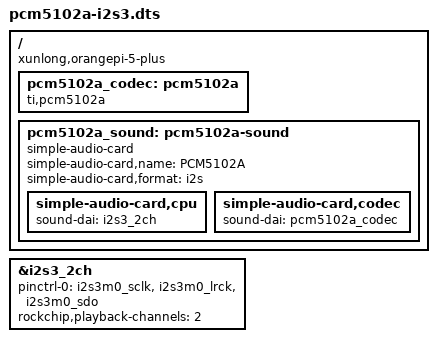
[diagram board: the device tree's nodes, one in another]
// Device Tree Overlay: PCM5102A I2S DAC on GPIO header (I2S3)
//
// Enables the RK3588/RK3588S I2S3 controller and registers a PCM5102A DAC
// connected to the 40-pin GPIO header as an ALSA sound card.
//
// Wiring:
//   Pin 35 (GPIO3_C2) → BCK  (bit clock)
//   Pin 38 (GPIO3_C0) → LRCK (L/R word select)
//   Pin 40 (GPIO3_B7) → DIN  (serial audio data)
//   Pin 1  (3.3V)     → VIN
//   Pin 6  (GND)      → GND + SCK (internal PLL mode)

/dts-v1/;
/plugin/;

/ {
    compatible = "xunlong,orangepi-5-plus", "rockchip,rk3588";

    fragment@0 {
        target = <&i2s3_2ch>;
        __overlay__ {
            status = "okay";
            #sound-dai-cells = <0>;
            pinctrl-names = "default";
            pinctrl-0 = <&i2s3m0_sclk &i2s3m0_lrck &i2s3m0_sdo>;
            rockchip,playback-channels = <2>;
        };
    };

    fragment@1 {
        target-path = "/";
        __overlay__ {
            pcm5102a_codec: pcm5102a {
                compatible = "ti,pcm5102a";
                #sound-dai-cells = <0>;
            };

            pcm5102a_sound: pcm5102a-sound {
                compatible = "simple-audio-card";
                simple-audio-card,name = "PCM5102A";
                simple-audio-card,format = "i2s";

                simple-audio-card,cpu {
                    sound-dai = <&i2s3_2ch>;
                };
                simple-audio-card,codec {
                    sound-dai = <&pcm5102a_codec>;
                };
            };
        };
    };
};
